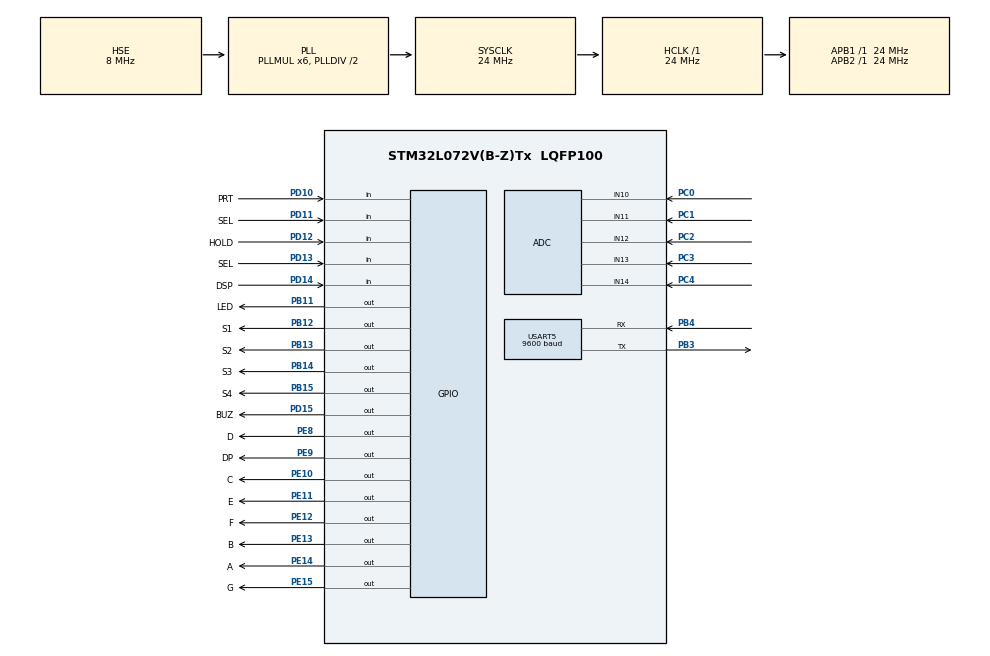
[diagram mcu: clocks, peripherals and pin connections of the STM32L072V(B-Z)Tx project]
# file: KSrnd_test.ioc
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ADC.DMAContinuousRequests=ENABLE
ADC.DiscontinuousConvMode=DISABLE
ADC.EOCSelection=ADC_EOC_SEQ_CONV
ADC.ExternalTrigConv=ADC_EXTERNALTRIGCONV_T6_TRGO
ADC.OversamplingMode=ENABLE
ADC.Ratio=ADC_OVERSAMPLING_RATIO_16
ADC.RightBitShift=ADC_RIGHTBITSHIFT_4
ADC.SamplingTime=ADC_SAMPLETIME_160CYCLES_5
Dma.ADC.0.Direction=DMA_PERIPH_TO_MEMORY
Dma.ADC.0.Instance=DMA1_Channel1
Dma.ADC.0.MemDataAlignment=DMA_MDATAALIGN_HALFWORD
Dma.ADC.0.MemInc=DMA_MINC_ENABLE
Dma.ADC.0.Mode=DMA_CIRCULAR
Dma.ADC.0.PeriphDataAlignment=DMA_PDATAALIGN_HALFWORD
Dma.ADC.0.PeriphInc=DMA_PINC_DISABLE
Dma.ADC.0.Priority=DMA_PRIORITY_LOW
Dma.Request0=ADC
Mcu.Family=STM32L0
Mcu.Name=STM32L072V(B-Z)Tx
Mcu.Package=LQFP100
NVIC.DMA1_Channel1_IRQn=true\:0\:0\:false\:false\:true\:false\:true\:true
NVIC.USART4_5_IRQn=true\:0\:0\:false\:false\:true\:true\:true\:true
PA13.Mode=Serial_Wire
PA13.Signal=SYS_SWDIO
PA14.Mode=Serial_Wire
PA14.Signal=SYS_SWCLK
PB11.GPIO_Label=LED
PB11.Signal=GPIO_Output
PB12.GPIO_Label=S1
PB12.Signal=GPIO_Output
PB13.GPIO_Label=S2
PB13.Signal=GPIO_Output
PB14.GPIO_Label=S3
PB14.Signal=GPIO_Output
PB15.GPIO_Label=S4
PB15.Signal=GPIO_Output
PB3.Mode=Asynchronous
PB3.Signal=USART5_TX
PB4.Mode=Asynchronous
PB4.Signal=USART5_RX
PC0.Mode=IN10
PC0.Signal=ADC_IN10
PC1.Mode=IN11
PC1.Signal=ADC_IN11
PC2.Mode=IN12
PC2.Signal=ADC_IN12
PC3.Mode=IN13
PC3.Signal=ADC_IN13
PC4.Mode=IN14
PC4.Signal=ADC_IN14
PD10.GPIO_Label=PRT
PD10.Signal=GPIO_Input
PD11.GPIO_Label=SEL
PD11.Signal=GPIO_Input
PD12.GPIO_Label=HOLD
PD12.Signal=GPIO_Input
PD13.GPIO_Label=SEL
PD13.Signal=GPIO_Input
PD14.GPIO_Label=DSP
PD14.Signal=GPIO_Input
PD15.GPIO_Label=BUZ
PD15.Signal=GPIO_Output
PE10.GPIO_Label=C
PE10.Signal=GPIO_Output
PE11.GPIO_Label=E
PE11.Signal=GPIO_Output
PE12.GPIO_Label=F
PE12.Signal=GPIO_Output
PE13.GPIO_Label=B
PE13.Signal=GPIO_Output
PE14.GPIO_Label=A
PE14.Signal=GPIO_Output
PE15.GPIO_Label=G
PE15.Signal=GPIO_Output
PE8.GPIO_Label=D
PE8.Signal=GPIO_Output
PE9.GPIO_Label=DP
PE9.Signal=GPIO_Output
PH0-OSC_IN.Mode=HSE-External-Oscillator
PH0-OSC_IN.Signal=RCC_OSC_IN
PH1-OSC_OUT.Mode=HSE-External-Oscillator
PH1-OSC_OUT.Signal=RCC_OSC_OUT
ProjectManager.HeapSize=0x200
ProjectManager.StackSize=0x400
ProjectManager.TargetToolchain=STM32CubeIDE
RCC.AHBFreq_Value=24000000
RCC.APB1Freq_Value=24000000
RCC.APB1TimFreq_Value=24000000
RCC.APB2Freq_Value=24000000
RCC.APB2TimFreq_Value=24000000
RCC.HCLKFreq_Value=24000000
RCC.HSE_VALUE=8000000
RCC.HSI16_VALUE=16000000
RCC.HSI48_VALUE=48000000
RCC.HSI_VALUE=16000000
RCC.LSE_VALUE=32768
RCC.MSI_VALUE=2097000
RCC.PLLMUL=RCC_PLLMUL_6
RCC.PLLSourceVirtual=RCC_PLLSOURCE_HSE
RCC.SYSCLKFreq_VALUE=24000000
RCC.SYSCLKSource=RCC_SYSCLKSOURCE_PLLCLK
RCC.VCOOutputFreq_Value=48000000
TIM6.Period=99
TIM6.Prescaler=2999
TIM6.TIM_MasterOutputTrigger=TIM_TRGO_UPDATE
USART5.BaudRate=9600
USART5.VirtualMode-Asynchronous=VM_ASYNC
VP_TIM6_VS_ClockSourceINT.Mode=Enable_Timer
board=custom

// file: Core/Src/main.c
/* USER CODE BEGIN Header */
/**
  ******************************************************************************
  * @file           : main.c
  * @brief          : Main program body
  ******************************************************************************
  * @attention
  *
  * Copyright (c) 2025 STMicroelectronics.
  * All rights reserved.
  *
  * This software is licensed under terms that can be found in the LICENSE file
  * in the root directory of this software component.
  * If no LICENSE file comes with this software, it is provided AS-IS.
  *
  ******************************************************************************
  */
/* USER CODE END Header */
#include "main.h"

ADC_HandleTypeDef hadc;
DMA_HandleTypeDef hdma_adc;

TIM_HandleTypeDef htim6;

UART_HandleTypeDef huart5;

void SystemClock_Config(void);
static void MX_GPIO_Init(void);
static void MX_DMA_Init(void);
static void MX_USART5_UART_Init(void);
static void MX_ADC_Init(void);
static void MX_TIM6_Init(void);
/* USER CODE BEGIN PFP */
void project_initialization(void);
void project_main(void);
/* USER CODE END PFP */

int main(void)
{

  /* MCU Configuration--------------------------------------------------------*/

  /* Reset of all peripherals, Initializes the Flash interface and the Systick. */
  HAL_Init();

  /* Configure the system clock */
  SystemClock_Config();

  /* Initialize all configured peripherals */
  MX_GPIO_Init();
  MX_DMA_Init();
  MX_USART5_UART_Init();
  MX_ADC_Init();
  MX_TIM6_Init();
  /* USER CODE BEGIN 2 */
  project_initialization();
  /* USER CODE END 2 */

  /* Infinite loop */
  /* USER CODE BEGIN WHILE */
  while (1)
  {
	  project_main();
    /* USER CODE END WHILE */

  }
}

void SystemClock_Config(void)
{
  RCC_OscInitTypeDef RCC_OscInitStruct = {0};
  RCC_ClkInitTypeDef RCC_ClkInitStruct = {0};

  /** Configure the main internal regulator output voltage
  */
  __HAL_PWR_VOLTAGESCALING_CONFIG(PWR_REGULATOR_VOLTAGE_SCALE1);

  /** Initializes the RCC Oscillators according to the specified parameters
  * in the RCC_OscInitTypeDef structure.
  */
  RCC_OscInitStruct.OscillatorType = RCC_OSCILLATORTYPE_HSE;
  RCC_OscInitStruct.HSEState = RCC_HSE_ON;
  RCC_OscInitStruct.PLL.PLLState = RCC_PLL_ON;
  RCC_OscInitStruct.PLL.PLLSource = RCC_PLLSOURCE_HSE;
  RCC_OscInitStruct.PLL.PLLMUL = RCC_PLLMUL_6;
  RCC_OscInitStruct.PLL.PLLDIV = RCC_PLLDIV_2;
  if (HAL_RCC_OscConfig(&RCC_OscInitStruct) != HAL_OK)
  {
    Error_Handler();
  }

  /** Initializes the CPU, AHB and APB buses clocks
  */
  RCC_ClkInitStruct.ClockType = RCC_CLOCKTYPE_HCLK|RCC_CLOCKTYPE_SYSCLK
                              |RCC_CLOCKTYPE_PCLK1|RCC_CLOCKTYPE_PCLK2;
  RCC_ClkInitStruct.SYSCLKSource = RCC_SYSCLKSOURCE_PLLCLK;
  RCC_ClkInitStruct.AHBCLKDivider = RCC_SYSCLK_DIV1;
  RCC_ClkInitStruct.APB1CLKDivider = RCC_HCLK_DIV1;
  RCC_ClkInitStruct.APB2CLKDivider = RCC_HCLK_DIV1;

  if (HAL_RCC_ClockConfig(&RCC_ClkInitStruct, FLASH_LATENCY_1) != HAL_OK)
  {
    Error_Handler();
  }
}

static void MX_ADC_Init(void)
{

  ADC_ChannelConfTypeDef sConfig = {0};

  /** Configure the global features of the ADC (Clock, Resolution, Data Alignment and number of conversion)
  */
  hadc.Instance = ADC1;
  hadc.Init.OversamplingMode = ENABLE;
  hadc.Init.Oversample.Ratio = ADC_OVERSAMPLING_RATIO_16;
  hadc.Init.Oversample.RightBitShift = ADC_RIGHTBITSHIFT_4;
  hadc.Init.Oversample.TriggeredMode = ADC_TRIGGEREDMODE_SINGLE_TRIGGER;
  hadc.Init.ClockPrescaler = ADC_CLOCK_SYNC_PCLK_DIV2;
  hadc.Init.Resolution = ADC_RESOLUTION_12B;
  hadc.Init.SamplingTime = ADC_SAMPLETIME_160CYCLES_5;
  hadc.Init.ScanConvMode = ADC_SCAN_DIRECTION_FORWARD;
  hadc.Init.DataAlign = ADC_DATAALIGN_RIGHT;
  hadc.Init.ContinuousConvMode = DISABLE;
  hadc.Init.DiscontinuousConvMode = DISABLE;
  hadc.Init.ExternalTrigConvEdge = ADC_EXTERNALTRIGCONVEDGE_RISING;
  hadc.Init.ExternalTrigConv = ADC_EXTERNALTRIGCONV_T6_TRGO;
  hadc.Init.DMAContinuousRequests = ENABLE;
  hadc.Init.EOCSelection = ADC_EOC_SEQ_CONV;
  hadc.Init.Overrun = ADC_OVR_DATA_PRESERVED;
  hadc.Init.LowPowerAutoWait = DISABLE;
  hadc.Init.LowPowerFrequencyMode = DISABLE;
  hadc.Init.LowPowerAutoPowerOff = DISABLE;
  if (HAL_ADC_Init(&hadc) != HAL_OK)
  {
    Error_Handler();
  }

  /** Configure for the selected ADC regular channel to be converted.
  */
  sConfig.Channel = ADC_CHANNEL_10;
  sConfig.Rank = ADC_RANK_CHANNEL_NUMBER;
  if (HAL_ADC_ConfigChannel(&hadc, &sConfig) != HAL_OK)
  {
    Error_Handler();
  }

  /** Configure for the selected ADC regular channel to be converted.
  */
  sConfig.Channel = ADC_CHANNEL_11;
  if (HAL_ADC_ConfigChannel(&hadc, &sConfig) != HAL_OK)
  {
    Error_Handler();
  }

  /** Configure for the selected ADC regular channel to be converted.
  */
  sConfig.Channel = ADC_CHANNEL_12;
  if (HAL_ADC_ConfigChannel(&hadc, &sConfig) != HAL_OK)
  {
    Error_Handler();
  }

  /** Configure for the selected ADC regular channel to be converted.
  */
  sConfig.Channel = ADC_CHANNEL_13;
  if (HAL_ADC_ConfigChannel(&hadc, &sConfig) != HAL_OK)
  {
    Error_Handler();
  }

  /** Configure for the selected ADC regular channel to be converted.
  */
  sConfig.Channel = ADC_CHANNEL_14;
  if (HAL_ADC_ConfigChannel(&hadc, &sConfig) != HAL_OK)
  {
    Error_Handler();
  }

}

static void MX_TIM6_Init(void)
{

  TIM_MasterConfigTypeDef sMasterConfig = {0};

  htim6.Instance = TIM6;
  htim6.Init.Prescaler = 2999;
  htim6.Init.CounterMode = TIM_COUNTERMODE_UP;
  htim6.Init.Period = 99;
  htim6.Init.AutoReloadPreload = TIM_AUTORELOAD_PRELOAD_DISABLE;
  if (HAL_TIM_Base_Init(&htim6) != HAL_OK)
  {
    Error_Handler();
  }
  sMasterConfig.MasterOutputTrigger = TIM_TRGO_UPDATE;
  sMasterConfig.MasterSlaveMode = TIM_MASTERSLAVEMODE_DISABLE;
  if (HAL_TIMEx_MasterConfigSynchronization(&htim6, &sMasterConfig) != HAL_OK)
  {
    Error_Handler();
  }

}

static void MX_USART5_UART_Init(void)
{

  huart5.Instance = USART5;
  huart5.Init.BaudRate = 9600;
  huart5.Init.WordLength = UART_WORDLENGTH_8B;
  huart5.Init.StopBits = UART_STOPBITS_1;
  huart5.Init.Parity = UART_PARITY_NONE;
  huart5.Init.Mode = UART_MODE_TX_RX;
  huart5.Init.HwFlowCtl = UART_HWCONTROL_NONE;
  huart5.Init.OverSampling = UART_OVERSAMPLING_16;
  huart5.Init.OneBitSampling = UART_ONE_BIT_SAMPLE_DISABLE;
  huart5.AdvancedInit.AdvFeatureInit = UART_ADVFEATURE_NO_INIT;
  if (HAL_UART_Init(&huart5) != HAL_OK)
  {
    Error_Handler();
  }

}

static void MX_DMA_Init(void)
{

  /* DMA controller clock enable */
  __HAL_RCC_DMA1_CLK_ENABLE();

  /* DMA interrupt init */
  /* DMA1_Channel1_IRQn interrupt configuration */
  HAL_NVIC_SetPriority(DMA1_Channel1_IRQn, 0, 0);
  HAL_NVIC_EnableIRQ(DMA1_Channel1_IRQn);

}

static void MX_GPIO_Init(void)
{
  GPIO_InitTypeDef GPIO_InitStruct = {0};

  /* GPIO Ports Clock Enable */
  __HAL_RCC_GPIOH_CLK_ENABLE();
  __HAL_RCC_GPIOC_CLK_ENABLE();
  __HAL_RCC_GPIOE_CLK_ENABLE();
  __HAL_RCC_GPIOB_CLK_ENABLE();
  __HAL_RCC_GPIOD_CLK_ENABLE();
  __HAL_RCC_GPIOA_CLK_ENABLE();

  /*Configure GPIO pin Output Level */
  HAL_GPIO_WritePin(GPIOE, D_Pin|DP_Pin|C_Pin|E_Pin
                          |F_Pin|B_Pin|A_Pin|G_Pin, GPIO_PIN_RESET);

  /*Configure GPIO pin Output Level */
  HAL_GPIO_WritePin(GPIOB, LED_Pin|S1_Pin|S2_Pin|S3_Pin
                          |S4_Pin, GPIO_PIN_RESET);

  /*Configure GPIO pin Output Level */
  HAL_GPIO_WritePin(BUZ_GPIO_Port, BUZ_Pin, GPIO_PIN_RESET);

  /*Configure GPIO pins : D_Pin DP_Pin C_Pin E_Pin
                           F_Pin B_Pin A_Pin G_Pin */
  GPIO_InitStruct.Pin = D_Pin|DP_Pin|C_Pin|E_Pin
                          |F_Pin|B_Pin|A_Pin|G_Pin;
  GPIO_InitStruct.Mode = GPIO_MODE_OUTPUT_PP;
  GPIO_InitStruct.Pull = GPIO_NOPULL;
  GPIO_InitStruct.Speed = GPIO_SPEED_FREQ_LOW;
  HAL_GPIO_Init(GPIOE, &GPIO_InitStruct);

  /*Configure GPIO pins : LED_Pin S1_Pin S2_Pin S3_Pin
                           S4_Pin */
  GPIO_InitStruct.Pin = LED_Pin|S1_Pin|S2_Pin|S3_Pin
                          |S4_Pin;
  GPIO_InitStruct.Mode = GPIO_MODE_OUTPUT_PP;
  GPIO_InitStruct.Pull = GPIO_NOPULL;
  GPIO_InitStruct.Speed = GPIO_SPEED_FREQ_LOW;
  HAL_GPIO_Init(GPIOB, &GPIO_InitStruct);

  /*Configure GPIO pins : PRT_Pin SEL_Pin HOLD_Pin SELD13_Pin
                           DSP_Pin */
  GPIO_InitStruct.Pin = PRT_Pin|SEL_Pin|HOLD_Pin|SELD13_Pin
                          |DSP_Pin;
  GPIO_InitStruct.Mode = GPIO_MODE_INPUT;
  GPIO_InitStruct.Pull = GPIO_NOPULL;
  HAL_GPIO_Init(GPIOD, &GPIO_InitStruct);

  /*Configure GPIO pin : BUZ_Pin */
  GPIO_InitStruct.Pin = BUZ_Pin;
  GPIO_InitStruct.Mode = GPIO_MODE_OUTPUT_PP;
  GPIO_InitStruct.Pull = GPIO_NOPULL;
  GPIO_InitStruct.Speed = GPIO_SPEED_FREQ_LOW;
  HAL_GPIO_Init(BUZ_GPIO_Port, &GPIO_InitStruct);

}

void Error_Handler(void)
{
  __disable_irq();
  while (1)
  {
  }
}
